VERSION "Honda Accord B-CAN transmitter grouping"

NS_ :

BS_:

BU_: METER MICU XXX UNKNOWN

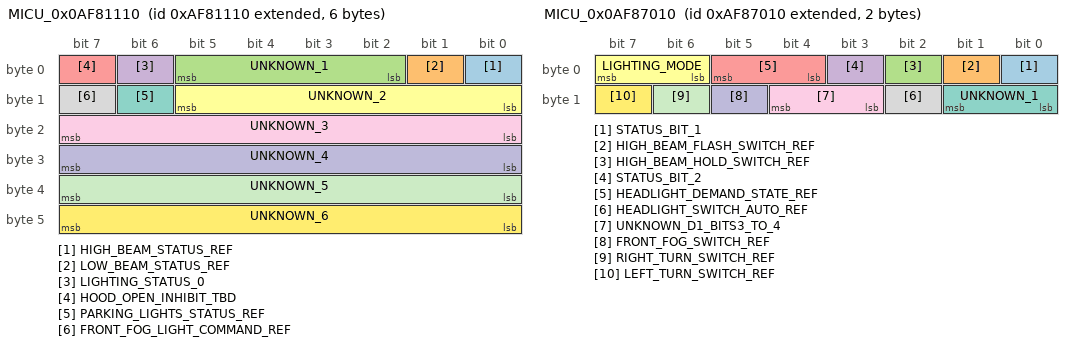
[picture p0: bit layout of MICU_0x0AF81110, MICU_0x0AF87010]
BO_ 2331513104 MICU_0x0AF81110: 6 MICU
 SG_ HIGH_BEAM_STATUS_REF : 0|1@1+ (1,0) [0|1] ""  UNKNOWN
 SG_ LOW_BEAM_STATUS_REF : 1|1@1+ (1,0) [0|1] ""  UNKNOWN
 SG_ UNKNOWN_1 : 2|4@1+ (1,0) [0|15] ""  UNKNOWN
 SG_ LIGHTING_STATUS_0 : 6|1@1+ (1,0) [0|1] ""  UNKNOWN
 SG_ HOOD_OPEN_INHIBIT_TBD : 7|1@1+ (1,0) [0|1] ""  UNKNOWN
 SG_ UNKNOWN_2 : 8|6@1+ (1,0) [0|63] ""  UNKNOWN
 SG_ PARKING_LIGHTS_STATUS_REF : 14|1@1+ (1,0) [0|1] ""  UNKNOWN
 SG_ FRONT_FOG_LIGHT_COMMAND_REF : 15|1@1+ (1,0) [0|1] ""  UNKNOWN
 SG_ UNKNOWN_3 : 16|8@1+ (1,0) [0|255] ""  UNKNOWN
 SG_ UNKNOWN_4 : 24|8@1+ (1,0) [0|255] ""  UNKNOWN
 SG_ UNKNOWN_5 : 32|8@1+ (1,0) [0|255] ""  UNKNOWN
 SG_ UNKNOWN_6 : 40|8@1+ (1,0) [0|255] ""  UNKNOWN

BO_ 2331537424 MICU_0x0AF87010: 2 MICU
 SG_ STATUS_BIT_1 : 0|1@1+ (1,0) [0|1] ""  UNKNOWN
 SG_ HIGH_BEAM_FLASH_SWITCH_REF : 1|1@1+ (1,0) [0|1] ""  UNKNOWN
 SG_ HIGH_BEAM_HOLD_SWITCH_REF : 2|1@1+ (1,0) [0|1] ""  UNKNOWN
 SG_ STATUS_BIT_2 : 3|1@1+ (1,0) [0|1] ""  UNKNOWN
 SG_ HEADLIGHT_DEMAND_STATE_REF : 4|2@1+ (1,0) [0|3] ""  UNKNOWN
 SG_ LIGHTING_MODE : 6|2@1+ (1,0) [0|3] ""  UNKNOWN
 SG_ UNKNOWN_1 : 8|2@1+ (1,0) [0|3] ""  UNKNOWN
 SG_ HEADLIGHT_SWITCH_AUTO_REF : 10|1@1+ (1,0) [0|1] ""  UNKNOWN
 SG_ UNKNOWN_D1_BITS3_TO_4 : 11|2@1+ (1,0) [0|3] ""  UNKNOWN
 SG_ FRONT_FOG_SWITCH_REF : 13|1@1+ (1,0) [0|1] ""  UNKNOWN
 SG_ RIGHT_TURN_SWITCH_REF : 14|1@1+ (1,0) [0|1] ""  UNKNOWN
 SG_ LEFT_TURN_SWITCH_REF : 15|1@1+ (1,0) [0|1] ""  UNKNOWN
CM_ SG_ 2331537424 HEADLIGHT_DEMAND_STATE_REF "Feeds instrument illumination control";

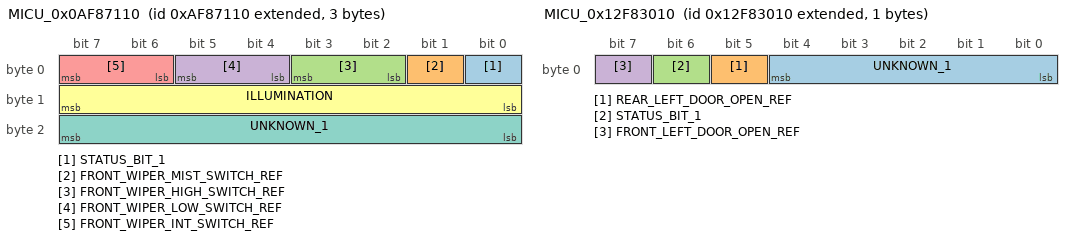
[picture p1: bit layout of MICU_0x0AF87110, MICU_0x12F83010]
BO_ 2331537680 MICU_0x0AF87110: 3 MICU
 SG_ STATUS_BIT_1 : 0|1@1+ (1,0) [0|1] ""  UNKNOWN
 SG_ FRONT_WIPER_MIST_SWITCH_REF : 1|1@1+ (1,0) [0|1] ""  UNKNOWN
 SG_ FRONT_WIPER_HIGH_SWITCH_REF : 2|2@1+ (1,0) [0|3] ""  UNKNOWN
 SG_ FRONT_WIPER_LOW_SWITCH_REF : 4|2@1+ (1,0) [0|3] ""  UNKNOWN
 SG_ FRONT_WIPER_INT_SWITCH_REF : 6|2@1+ (1,0) [0|3] ""  UNKNOWN
 SG_ ILLUMINATION : 8|8@1+ (1,0) [0|255] ""  UNKNOWN
 SG_ UNKNOWN_1 : 16|8@1+ (1,0) [0|255] ""  UNKNOWN
VAL_ 2331537680 FRONT_WIPER_HIGH_SWITCH_REF 0 "OFF" 1 "SELECTED" 3 "CONTACT_CONFLICT_REF" ;
VAL_ 2331537680 FRONT_WIPER_LOW_SWITCH_REF 0 "OFF" 1 "SELECTED" 3 "CONTACT_CONFLICT_REF" ;
VAL_ 2331537680 FRONT_WIPER_INT_SWITCH_REF 0 "OFF" 1 "SELECTED" 3 "CONTACT_CONFLICT_REF" ;

BO_ 2398622992 MICU_0x0EF81510: 1 MICU
 SG_ UNKNOWN_1 : 0|8@1+ (1,0) [0|255] ""  UNKNOWN

BO_ 2398625808 MICU_0x0EF82010: 1 MICU
 SG_ UNKNOWN_1 : 0|8@1+ (1,0) [0|255] ""  UNKNOWN

BO_ 2465730576 MICU_0x12F81010: 5 MICU
 SG_ UNKNOWN_D0_LOW_BITS : 0|5@1+ (1,0) [0|31] ""  UNKNOWN
 SG_ DRIVER_DOOR_CHIME_INPUT_REF : 5|1@1+ (1,0) [0|1] ""  UNKNOWN
 SG_ UNKNOWN_D0_HIGH_BITS : 6|2@1+ (1,0) [0|3] ""  UNKNOWN
 SG_ UNKNOWN_2 : 8|8@1+ (1,0) [0|255] ""  UNKNOWN
 SG_ UNKNOWN_D2_LOW_BITS : 16|3@1+ (1,0) [0|7] ""  UNKNOWN
 SG_ RIGHT_TURN_FLASH_PHASE_REF : 19|1@1+ (1,0) [0|1] ""  UNKNOWN
 SG_ LEFT_TURN_FLASH_PHASE_REF : 20|1@1+ (1,0) [0|1] ""  UNKNOWN
 SG_ HAZARD_SWITCH_STATUS_REF : 21|1@1+ (1,0) [0|1] ""  UNKNOWN
 SG_ UNKNOWN_D2_HIGH_BITS : 22|2@1+ (1,0) [0|3] ""  UNKNOWN
 SG_ UNKNOWN_D3_LOW_BITS : 24|4@1+ (1,0) [0|15] ""  UNKNOWN
 SG_ REAR_RIGHT_DOOR_OPEN_ALT_REF : 28|1@1+ (1,0) [0|1] ""  UNKNOWN
 SG_ REAR_LEFT_DOOR_OPEN_ALT_REF : 29|1@1+ (1,0) [0|1] ""  UNKNOWN
 SG_ UNKNOWN_D3_BIT6 : 30|1@1+ (1,0) [0|1] ""  UNKNOWN
 SG_ BACKUP_LIGHT_SWITCH_REF : 31|1@1+ (1,0) [0|1] ""  UNKNOWN
 SG_ UNKNOWN_D4_LOW_BITS : 32|6@1+ (1,0) [0|63] ""  UNKNOWN
 SG_ RIGHT_TURN_ONE_TOUCH_REQUEST_REF : 38|1@1+ (1,0) [0|1] ""  UNKNOWN
 SG_ LEFT_TURN_ONE_TOUCH_REQUEST_REF : 39|1@1+ (1,0) [0|1] ""  UNKNOWN
VAL_ 2465730576 RIGHT_TURN_FLASH_PHASE_REF 0 "OFF_PHASE" 1 "ON_PHASE" ;
VAL_ 2465730576 LEFT_TURN_FLASH_PHASE_REF 0 "OFF_PHASE" 1 "ON_PHASE" ;
CM_ SG_ 2465730576 DRIVER_DOOR_CHIME_INPUT_REF "Qualifies the chime when the driver door is open.";
CM_ SG_ 2465730576 UNKNOWN_D2_HIGH_BITS "Feeds LIN 0x25 status";

BO_ 2465737744 MICU_0x12F82C10: 1 MICU
 SG_ UNKNOWN_1 : 0|8@1+ (1,0) [0|255] ""  UNKNOWN

BO_ 2465738768 MICU_0x12F83010: 1 MICU
 SG_ UNKNOWN_1 : 0|5@1+ (1,0) [0|31] ""  UNKNOWN
 SG_ REAR_LEFT_DOOR_OPEN_REF : 5|1@1+ (1,0) [0|1] ""  UNKNOWN
 SG_ STATUS_BIT_1 : 6|1@1+ (1,0) [0|1] ""  UNKNOWN
 SG_ FRONT_LEFT_DOOR_OPEN_REF : 7|1@1+ (1,0) [0|1] ""  UNKNOWN

BO_ 2465739024 MICU_0x12F83110: 1 MICU
 SG_ UNKNOWN_1 : 0|8@1+ (1,0) [0|255] ""  UNKNOWN

BO_ 2465739280 MICU_0x12F83210: 1 MICU
 SG_ UNKNOWN_1 : 0|8@1+ (1,0) [0|255] ""  UNKNOWN

BO_ 2465739792 MICU_0x12F83410: 1 MICU
 SG_ UNKNOWN_1 : 0|8@1+ (1,0) [0|255] ""  UNKNOWN

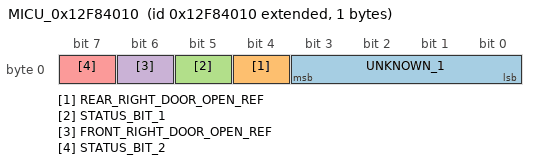
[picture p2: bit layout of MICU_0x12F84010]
BO_ 2465742864 MICU_0x12F84010: 1 MICU
 SG_ UNKNOWN_1 : 0|4@1+ (1,0) [0|15] ""  UNKNOWN
 SG_ REAR_RIGHT_DOOR_OPEN_REF : 4|1@1+ (1,0) [0|1] ""  UNKNOWN
 SG_ STATUS_BIT_1 : 5|1@1+ (1,0) [0|1] ""  UNKNOWN
 SG_ FRONT_RIGHT_DOOR_OPEN_REF : 6|1@1+ (1,0) [0|1] ""  UNKNOWN
 SG_ STATUS_BIT_2 : 7|1@1+ (1,0) [0|1] ""  UNKNOWN

BO_ 2465743120 MICU_0x12F84110: 1 MICU
 SG_ UNKNOWN_1 : 0|8@1+ (1,0) [0|255] ""  UNKNOWN

BO_ 2465743376 MICU_0x12F84210: 1 MICU
 SG_ UNKNOWN_1 : 0|8@1+ (1,0) [0|255] ""  UNKNOWN

BO_ 2465743632 MICU_0x12F84310: 1 MICU
 SG_ UNKNOWN_1 : 0|7@1+ (1,0) [0|127] ""  UNKNOWN
 SG_ TRUNK_OPEN_TBD : 7|1@1+ (1,0) [0|1] ""  UNKNOWN

BO_ 2465757200 MICU_0x12F87810: 1 MICU
 SG_ UNKNOWN_1 : 0|8@1+ (1,0) [0|255] ""  UNKNOWN
